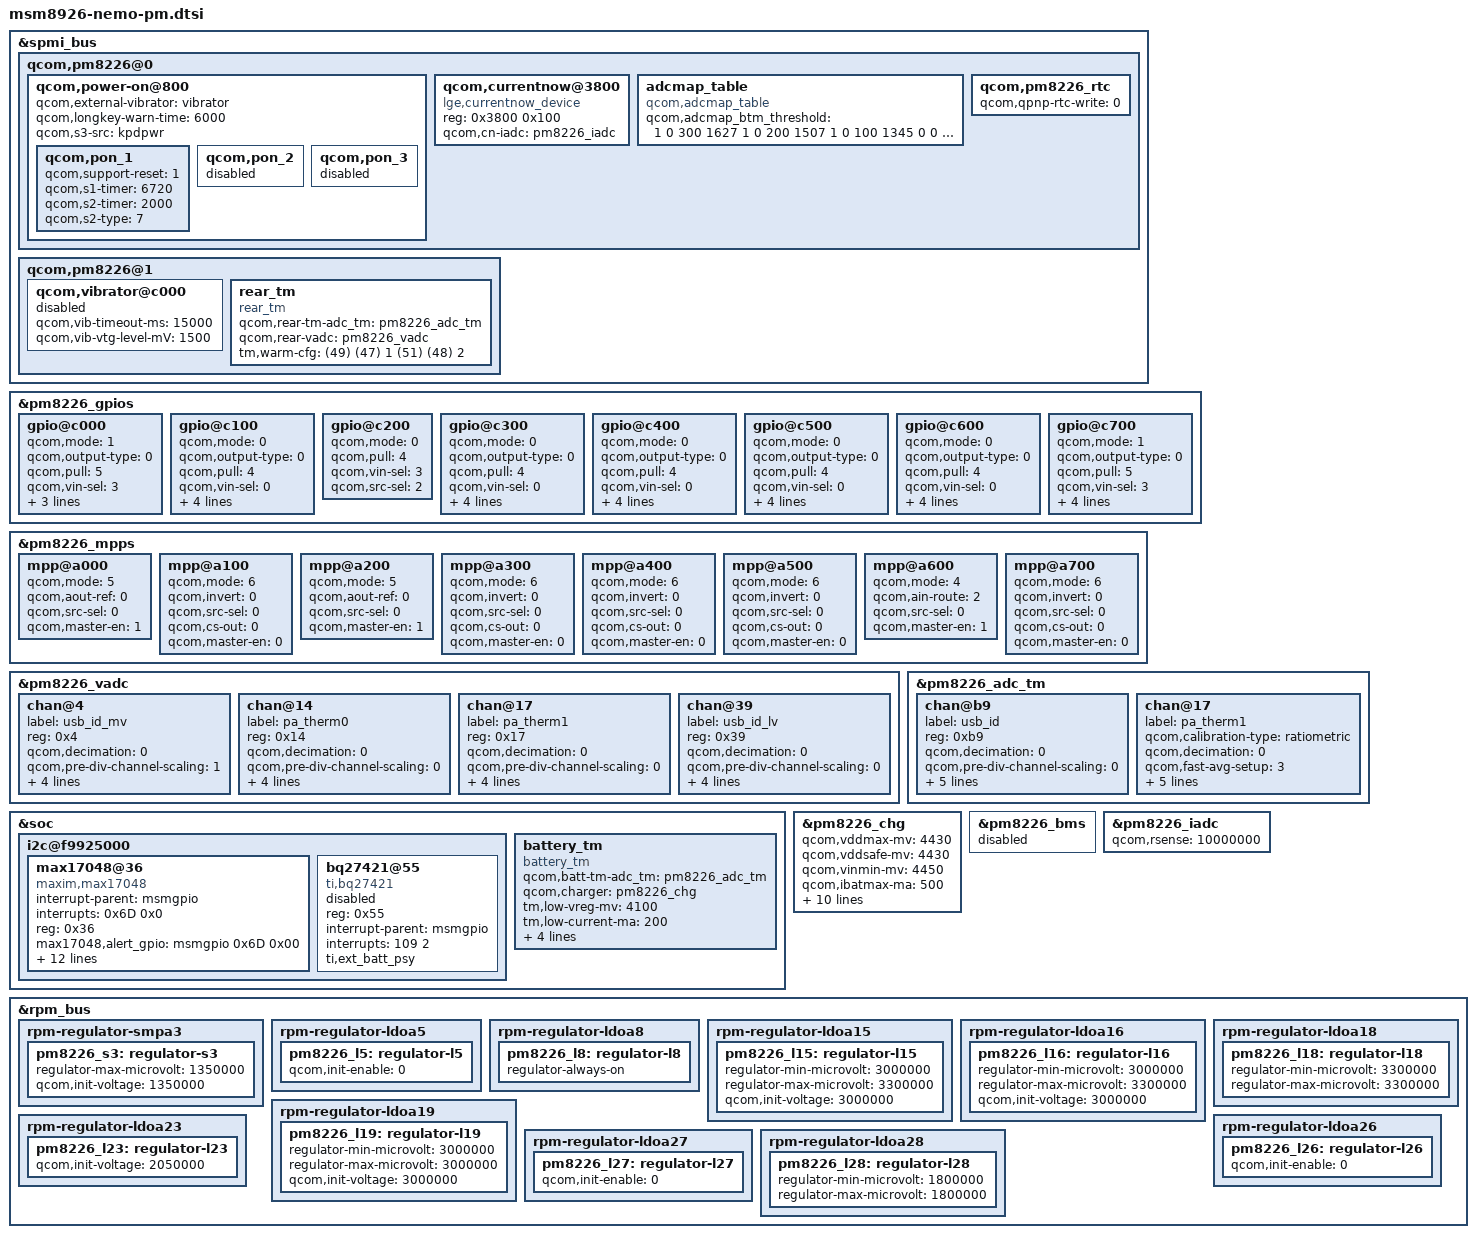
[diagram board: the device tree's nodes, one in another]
/* Copyright (c) 2014,2015 LGE Inc. All rights reserved.
 *
 * This program is free software; you can redistribute it and/or modify
* it under the terms of the GNU General Public License version 2 and
* only version 2 as published by the Free Software Foundation.
*
* This program is distributed in the hope that it will be useful,
* but WITHOUT ANY WARRANTY; without even the implied warranty of
* MERCHANTABILITY or FITNESS FOR A PARTICULAR PURPOSE.  See the
* GNU General Public License for more details.
*/

&spmi_bus {
	qcom,pm8226@0 {
		qcom,power-on@800 {
			qcom,external-vibrator = <&vibrator>;
			qcom,longkey-warn-time = <6000>;
			qcom,s3-src = "kpdpwr";
			qcom,pon_1 {
				qcom,support-reset = <1>;
				qcom,s1-timer = <6720>;
				qcom,s2-timer = <2000>;
				qcom,s2-type = <7>;
			};
			qcom,pon_2 {
				status = "disabled";
			};
			qcom,pon_3 {
				status = "disabled";
			};
		};

		qcom,currentnow@3800 {
			compatible ="lge,currentnow_device";
			reg = <0x3800 0x100>;
			qcom,cn-iadc = <&pm8226_iadc>;
			status = "okay";
		};

		/*
		 * Since negative numbers are not allowed in device trees,
		 * the first two digits here specify if the last two are
		 * negative: 0 == positive, 1 == negative.
		 */
		adcmap_table {
			compatible = "qcom,adcmap_table";
			status = "okay";
			qcom,adcmap_btm_threshold = <
				1 0 300 1627
				1 0 200 1507
				1 0 100 1345
				0 0 0 1159
				0 0 10 1139
				0 0 20 1120
				0 0 30 1101
				0 0 40 1082
				0 0 50 1064
				0 0 60 1045
				0 0 70 1026
				0 0 80 1008
				0 0 90 989
				0 0 100 972
				0 0 110 954
				0 0 120 936
				0 0 130 919
				0 0 140 902
				0 0 150 885
				0 0 160 869
				0 0 170 853
				0 0 180 837
				0 0 190 822
				0 0 200 807
				0 0 210 792
				0 0 220 777
				0 0 230 763
				0 0 240 750
				0 0 250 737
				0 0 260 724
				0 0 270 711
				0 0 280 699
				0 0 290 687
				0 0 300 675
				0 0 310 664
				0 0 320 653
				0 0 330 643
				0 0 340 633
				0 0 350 623
				0 0 360 613
				0 0 370 604
				0 0 380 595
				0 0 390 586
				0 0 400 578
				0 0 410 570
				0 0 420 562
				0 0 430 555
				0 0 440 547
				0 0 450 540
				0 0 460 533
				0 0 470 527
				0 0 480 521
				0 0 490 515
				0 0 500 509
				0 0 510 503
				0 0 520 498
				0 0 530 492
				0 0 540 487
				0 0 550 482
				0 0 560 478
				0 0 570 473
				0 0 580 469
				0 0 590 465
				0 0 600 461
				0 0 610 457
				0 0 620 453
				0 0 630 449
				0 0 640 446
				0 0 650 442
				0 0 660 439
				0 0 670 436
				0 0 680 433
				0 0 690 430
				0 0 700 427
				0 0 710 425
				0 0 720 422
				0 0 730 420
				0 0 740 417
				0 0 750 415
				0 0 760 413
				0 0 770 411
				0 0 780 409
				0 0 790 407>;
		};
		qcom,pm8226_rtc {
			qcom,qpnp-rtc-write = <0>;
		};
	};

	qcom,pm8226@1 {
		qcom,vibrator@c000 {
                        status = "disabled";
                        qcom,vib-timeout-ms = <15000>;
                        qcom,vib-vtg-level-mV = <1500>;
		};

		rear_tm: rear_tm {
			compatible = "rear_tm";
			status = "okay";
			qcom,rear-tm-adc_tm = <&pm8226_adc_tm>;
			qcom,rear-vadc = <&pm8226_vadc>;
			tm,warm-cfg = <
				(49) (47) 1
				(51) (48) 2>;
		};
	};
};

&pm8226_gpios {
	gpio@c000 { /* GPIO 1 */    /* PMIC_AUDIO_REF_CLK */
		/* XO_PMIC_CDC_MCLK enable for tapan codec */
		qcom,mode = <1>;        /* Digital output */
		qcom,output-type = <0>; /* CMOS logic */
		qcom,pull = <5>;        /* QPNP_PIN_PULL_NO*/
		qcom,vin-sel = <3>;     /* QPNP_PIN_VIN2 */
		qcom,out-strength = <3>;/* QPNP_PIN_OUT_STRENGTH_HIGH */
		qcom,src-sel = <2>;     /* QPNP_PIN_SEL_FUNC_1 */
		qcom,master-en = <1>;   /* Enable GPIO */
	};

	gpio@c100 { /* GPIO 2 */    /* NC config */
		qcom,mode = <0>;        /* QPNP_PIN_MODE_DIG_IN */
		qcom,output-type = <0>; /* QPNP_PIN_OUT_BUF_CMOS */
		qcom,pull = <4>;        /* QPNP_PIN_PULL_DN */
		qcom,vin-sel = <0>;     /* QPNP_PIN_VIN0 */
		qcom,invert = <0>;      /* QPNP_PIN_INVERT_DISABLE */
		qcom,out-strength = <1>;/* QPNP_PIN_OUT_STRENGTH_LOW */
		qcom,src-sel = <0>;     /* QPNP_PIN_SEL_FUNC_CONSTANT */
		qcom,master-en = <0>;   /* Disable GPIO */
	};

	gpio@c200 { /* GPIO 3 */    /* NFC_CLK_REQ */
		qcom,mode = <0>;        /* QPNP_PIN_MODE_DIG_IN */
		qcom,pull = <4>;        /* QPNP_PIN_PULL_DN - Not Fixed */
		qcom,vin-sel = <3>;     /* QPNP_PIN_VIN2 */
		qcom,src-sel = <2>;     /* QPNP_PIN_SEL_FUNC_1 */
	};

	gpio@c300 { /* GPIO 4 */    /* NC config */
		qcom,mode = <0>;        /* QPNP_PIN_MODE_DIG_IN */
		qcom,output-type = <0>; /* QPNP_PIN_OUT_BUF_CMOS */
		qcom,pull = <4>;        /* QPNP_PIN_PULL_DN */
		qcom,vin-sel = <0>;     /* QPNP_PIN_VIN0 */
		qcom,invert = <0>;      /* QPNP_PIN_INVERT_DISABLE */
		qcom,out-strength = <1>;/* QPNP_PIN_OUT_STRENGTH_LOW */
		qcom,src-sel = <0>;     /* QPNP_PIN_SEL_FUNC_CONSTANT */
		qcom,master-en = <0>;   /* Disable GPIO */
	};

	gpio@c400 { /* GPIO 5 */    /* NC config */
		qcom,mode = <0>;        /* QPNP_PIN_MODE_DIG_IN */
		qcom,output-type = <0>; /* QPNP_PIN_OUT_BUF_CMOS */
		qcom,pull = <4>;        /* QPNP_PIN_PULL_DN */
		qcom,vin-sel = <0>;     /* QPNP_PIN_VIN0 */
		qcom,invert = <0>;      /* QPNP_PIN_INVERT_DISABLE */
		qcom,out-strength = <1>;/* QPNP_PIN_OUT_STRENGTH_LOW */
		qcom,src-sel = <0>;     /* QPNP_PIN_SEL_FUNC_CONSTANT */
		qcom,master-en = <0>;   /* Disable GPIO */
	};

	gpio@c500 { /* GPIO 6 */    /* NC config */
		qcom,mode = <0>;        /* QPNP_PIN_MODE_DIG_IN */
		qcom,output-type = <0>; /* QPNP_PIN_OUT_BUF_CMOS */
		qcom,pull = <4>;        /* QPNP_PIN_PULL_DN */
		qcom,vin-sel = <0>;     /* QPNP_PIN_VIN0 */
		qcom,invert = <0>;      /* QPNP_PIN_INVERT_DISABLE */
		qcom,out-strength = <1>;/* QPNP_PIN_OUT_STRENGTH_LOW */
		qcom,src-sel = <0>;     /* QPNP_PIN_SEL_FUNC_CONSTANT */
		qcom,master-en = <0>;   /* Disable GPIO */
	};

	gpio@c600 { /* GPIO 7 */    /* NC config */
		qcom,mode = <0>;        /* QPNP_PIN_MODE_DIG_IN */
		qcom,output-type = <0>; /* QPNP_PIN_OUT_BUF_CMOS */
		qcom,pull = <4>;        /* QPNP_PIN_PULL_DN */
		qcom,vin-sel = <0>;     /* QPNP_PIN_VIN0 */
		qcom,invert = <0>;      /* QPNP_PIN_INVERT_DISABLE */
		qcom,out-strength = <1>;/* QPNP_PIN_OUT_STRENGTH_LOW */
		qcom,src-sel = <0>;     /* QPNP_PIN_SEL_FUNC_CONSTANT */
		qcom,master-en = <0>;   /* Disable GPIO */
	};

	gpio@c700 { /* GPIO 8 */    /* BOOST_BYP_BYP */
		qcom,mode = <1>;        /* QPNP_PIN_MODE_DIG_OUT */
		qcom,output-type = <0>; /* QPNP_PIN_OUT_BUF_CMOS */
		qcom,pull = <5>;        /* QPNP_PIN_PULL_NO */
		qcom,vin-sel = <3>;     /* QPNP_PIN_VIN2 */
		qcom,invert = <1>;      /* QPNP_PIN_INVERT_ENABLE */
		qcom,out-strength = <2>;/* QPNP_PIN_OUT_STRENGTH_MED */
		qcom,src-sel = <0>;     /* QPNP_PIN_SEL_FUNC_CONSTANT */
		qcom,master-en = <1>;   /* Enable GPIO */
	};
};

&pm8226_mpps {
	mpp@a000 { /* MPP 1 */      /* VREF_MSM_PX */
		qcom,mode = <5>;        /* QPNP_PIN_MODE_AOUT */
		qcom,aout-ref = <0>;    /* QPNP_PIN_AOUT_1V25 - Not Fixed */
		qcom,src-sel = <0>;     /* QPNP_PIN_SEL_FUNC_CONSTANT - QCT TBD */
		qcom,master-en = <1>;   /* Enable MPP */
	};

	mpp@a100 { /* MPP 2 */      /* NC config */
		qcom,mode = <6>;        /* QPNP_PIN_MODE_SINK */
		qcom,invert = <0>;      /* QPNP_PIN_INVERT_DISABLE */
		qcom,src-sel = <0>;     /* QPNP_PIN_SEL_FUNC_CONSTANT - QCT TBD */
		qcom,cs-out = <0>;      /* QPNP_PIN_CS_OUT_5MA */
		qcom,master-en = <0>;   /* DISABLE MPP */
	};

	mpp@a200 { /* MPP 3 */     /* VREF_LDO */
		qcom,mode = <5>;        /* QPNP_PIN_MODE_AOUT */
		qcom,aout-ref = <0>;    /* QPNP_PIN_AOUT_1V25 */
		qcom,src-sel = <0>;     /* QPNP_PIN_SEL_FUNC_CONSTANT - QCT TBD */
		qcom,master-en = <1>;   /* Enable MPP */
	};

	mpp@a300 { /* MPP 4 */      /* NC config */
		qcom,mode = <6>;        /* QPNP_PIN_MODE_SINK */
		qcom,invert = <0>;      /* QPNP_PIN_INVERT_DISABLE */
		qcom,src-sel = <0>;     /* QPNP_PIN_SEL_FUNC_CONSTANT - QCT TBD */
		qcom,cs-out = <0>;      /* QPNP_PIN_CS_OUT_5MA */
		qcom,master-en = <0>;   /* DISABLE MPP */
	};

	mpp@a400 { /* MPP 5 */      /* NC config */
		qcom,mode = <6>;        /* QPNP_PIN_MODE_SINK */
		qcom,invert = <0>;      /* QPNP_PIN_INVERT_DISABLE */
		qcom,src-sel = <0>;     /* QPNP_PIN_SEL_FUNC_CONSTANT - QCT TBD */
		qcom,cs-out = <0>;      /* QPNP_PIN_CS_OUT_5MA */
		qcom,master-en = <0>;   /* DISABLE MPP */
	};

	mpp@a500 { /* MPP 6 */      /* NC config */
		qcom,mode = <6>;        /* QPNP_PIN_MODE_SINK */
		qcom,invert = <0>;      /* QPNP_PIN_INVERT_DISABLE */
		qcom,src-sel = <0>;     /* QPNP_PIN_SEL_FUNC_CONSTANT - QCT TBD */
		qcom,cs-out = <0>;      /* QPNP_PIN_CS_OUT_5MA */
		qcom,master-en = <0>;   /* DISABLE MPP */
	};

	mpp@a600 { /* MPP 7 */      /* BOARD_ID */
		qcom,mode = <4>;        /* AIN input */
		qcom,ain-route = <2>;   /* QPNP_PIN_AIN_AMUX_CH7 */
		qcom,src-sel = <0>;     /* QPNP_PIN_SEL_FUNC_CONSTANT */
		qcom,master-en = <1>;   /* Enable MPP */
	};

	mpp@a700 { /* MPP 8 */      /* NC config */
		qcom,mode = <6>;        /* QPNP_PIN_MODE_SINK */
		qcom,invert = <0>;      /* QPNP_PIN_INVERT_DISABLE */
		qcom,src-sel = <0>;     /* QPNP_PIN_SEL_FUNC_CONSTANT - QCT TBD */
		qcom,cs-out = <0>;      /* QPNP_PIN_CS_OUT_5MA */
		qcom,master-en = <0>;   /* DISABLE MPP */
	};
};

&pm8226_vadc {
	chan@4 {
		label = "usb_id_mv";
		reg = <0x4>;
		qcom,decimation = <0>;
		qcom,pre-div-channel-scaling = <1>;
		qcom,calibration-type = "absolute";
		qcom,scale-function = <0>;
		qcom,hw-settle-time = <0>;
		qcom,fast-avg-setup = <0>;
	};

	chan@14 {
		label = "pa_therm0";
		reg = <0x14>;
		qcom,decimation = <0>;
		qcom,pre-div-channel-scaling = <0>;
		qcom,calibration-type = "ratiometric";
		qcom,scale-function = <2>;
		qcom,hw-settle-time = <2>;
		qcom,fast-avg-setup = <0>;
	};

	chan@17 {
		label = "pa_therm1";
		reg = <0x17>;
		qcom,decimation = <0>;
		qcom,pre-div-channel-scaling = <0>;
		qcom,calibration-type = "ratiometric";
		qcom,scale-function = <2>;
		qcom,hw-settle-time = <2>;
		qcom,fast-avg-setup = <0>;
	};

	chan@39 {
		label = "usb_id_lv";
		reg = <0x39>;
		qcom,decimation = <0>;
		qcom,pre-div-channel-scaling = <0>;
		qcom,calibration-type = "absolute";
		qcom,scale-function = <0>;
		qcom,hw-settle-time = <0>;
		qcom,fast-avg-setup = <0>;
	};

};

&pm8226_adc_tm {
	chan@b9 {
		label = "usb_id";
		reg = <0xb9>;
		qcom,decimation = <0>;
		qcom,pre-div-channel-scaling = <0>;
		qcom,calibration-type = "ratiometric";
		qcom,scale-function = <2>;
		qcom,hw-settle-time = <2>;
		qcom,fast-avg-setup = <3>;
		qcom,btm-channel-number = <0x88>;
	};
	chan@17 {
		label = "pa_therm1";
		qcom,calibration-type = "ratiometric";
		qcom,decimation = <0>;
		qcom,fast-avg-setup = <3>;
		qcom,hw-settle-time = <2>;
		qcom,pre-div-channel-scaling = <0>;
		qcom,scale-function = <7>;
		qcom,meas-interval-timer-idx = <0>;
		reg = <0x17>;
		/delete-property/ qcom,thermal-node;
	};
};

&soc {
	i2c@f9925000 {
		max17048@36 {
			compatible = "maxim,max17048";
			status = "okay";
			interrupt-parent = <&msmgpio>;
			interrupts = <0x6D 0x0>;
			reg = <0x36>;
			max17048,alert_gpio = <&msmgpio 0x6D 0x00>;
			max17048,rcomp = <32>;
			max17048,rcomp-co-hot = <0>;
			max17048,rcomp-co-cold = <5687>;
			max17048,alert_threshold = <2>;
			max17048,max-mvolt = <4400>;
			max17048,min-mvolt = <3200>;
			max17048,full-soc = <970>;
			max17048,empty-soc = <10>;
			max17048,batt-tech = <2>;
			max17048,fcc-mah = <570>;
			max17048,ext-batt-psy;
			qcom,chg-iadc = <&pm8226_iadc>;
		};
		bq27421@55 {
			compatible = "ti,bq27421";
			reg = <0x55>;
			interrupt-parent = <&msmgpio>;
			interrupts = <109 2>;
			ti,ext_batt_psy;
			status = "disabled";
		};
	};

	battery_tm {
		compatible = "battery_tm";
		status = "ok";
		qcom,batt-tm-adc_tm = <&pm8226_adc_tm>;
		qcom,charger = <&pm8226_chg>;
		tm,low-vreg-mv = <4100>;
		tm,low-current-ma = <200>;
		tm,warm-cfg = <
			 (-50) (-100) (450) 0 1
			 (450)  (430) (550) 1 2
			 (550)  (430) (600) 2 2
			 (600)  (430) (790) 3 2>;
		tm,cool-cfg = <
			(-100) (-300) (-50) 2 7
			 (430) (-100) (450) 0 1>;
	};
};

&pm8226_chg {
	qcom,vddmax-mv = <4430>;
	qcom,vddsafe-mv = <4430>;
	qcom,vinmin-mv = <4450>;
	qcom,ibatmax-ma= <500>;
	qcom,ibatterm-ma = <40>;
	qcom,ibatsafe-ma = <550>;
	qcom,vbatdet-delta-mv = <150>;
	qcom,tchg-mins = <480>;
	qcom,thermal-mitigation = <0>; /* disable */
	qcom,btc-disabled;
	qcom,warm-bat-decidegc = <0>; /* disable */
	qcom,cool-bat-decidegc = <0>; /* disable */
	qcom,step-dwn-offset-ma = <250>;
	qcom,step-dwn-thr-mv = <4250>;
};

&pm8226_bms{
	status = "disabled";
};

&pm8226_iadc {
       qcom,rsense = <10000000>;
};

&rpm_bus {
	rpm-regulator-smpa3 {
		status = "okay";
		pm8226_s3: regulator-s3 {
			regulator-max-microvolt = <1350000>;
			qcom,init-voltage = <1350000>;
			status = "okay";
		};
	};
	rpm-regulator-ldoa5 {
		status = "okay";
		pm8226_l5: regulator-l5 {
			qcom,init-enable = <0>;
			status = "okay";
		};
	};
	rpm-regulator-ldoa8 {
		status = "okay";
		pm8226_l8: regulator-l8 {
			regulator-always-on;
			status="okay";
		};
	};
	rpm-regulator-ldoa15 {
		status = "okay";
		pm8226_l15: regulator-l15 {
			regulator-min-microvolt = <3000000>;
			regulator-max-microvolt = <3300000>;
			qcom,init-voltage = <3000000>;
			status = "okay";
		};
	};
	rpm-regulator-ldoa16 {
		status = "okay";
		pm8226_l16: regulator-l16 {
			regulator-min-microvolt = <3000000>;
			regulator-max-microvolt = <3300000>;
			qcom,init-voltage = <3000000>;
			status = "okay";
		};
	};
	rpm-regulator-ldoa18 {
		status = "okay";
		pm8226_l18: regulator-l18 {
			regulator-min-microvolt = <3300000>;
			regulator-max-microvolt = <3300000>;
			status = "okay";
		};
	};
	rpm-regulator-ldoa19 {
		status = "okay";
		pm8226_l19: regulator-l19 {
			regulator-min-microvolt = <3000000>;
			regulator-max-microvolt = <3000000>;
			qcom,init-voltage = <3000000>;
			status = "okay";
		};
	};
	rpm-regulator-ldoa23 {
		pm8226_l23: regulator-l23 {
			qcom,init-voltage = <2050000>;
		};
	};
	rpm-regulator-ldoa26 {
		status = "okay";
		pm8226_l26: regulator-l26 {
			qcom,init-enable = <0>;
			status = "okay";
		};
	};
	rpm-regulator-ldoa27 {
		status = "okay";
		pm8226_l27: regulator-l27 {
			qcom,init-enable = <0>;
			status = "okay";
		};
	};
	rpm-regulator-ldoa28 {
		status = "okay";
		pm8226_l28: regulator-l28 {
			regulator-min-microvolt = <1800000>;
			regulator-max-microvolt = <1800000>;
			status = "okay";
		};
	};
};
